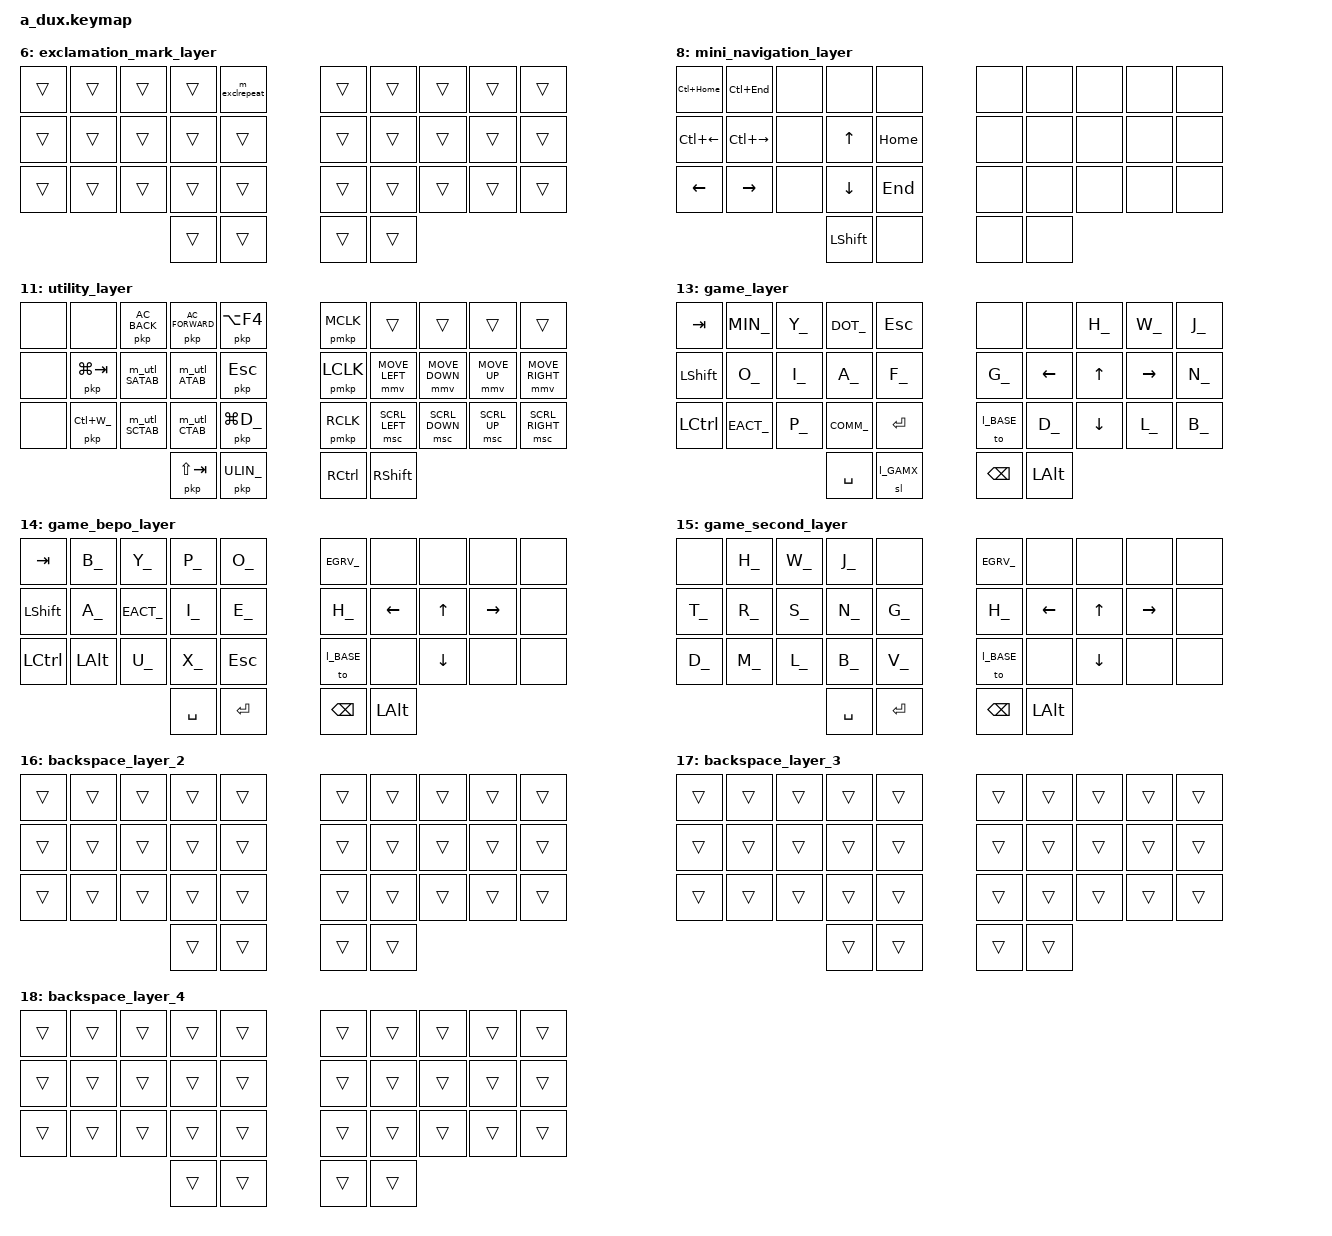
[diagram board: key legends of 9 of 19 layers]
#include <behaviors.dtsi>
#include <dt-bindings/zmk/keys.h>
#include <dt-bindings/zmk/bt.h>
#include <dt-bindings/zmk/outputs.h>
#include <dt-bindings/zmk/pointing.h>

#include "bepo_bindings.h"
#include "settings.dtsi"


// SPECIAL MODS ----------------------
#define SUPR(x)     LS(LC(LA(x)))
#define HYPR(x)  LG(LS(LC(LA(x))))

// EXTERNAL INTEGRATIONS ------------------------
#define M2_BRI_U     SUPR(U_)  // + brightness external display           (ahk + controlmymonitor)
#define M2_BRI_D     SUPR(Z_)  // - brightness external display           (ahk + controlmymonitor)
#define DISPLAY_OFF  SUPR(Q_)  // turns screen off                        (ahk + controlmymonitor)
#define TOG_DISPLAY  SUPR(Y_)  // toggles extend/external display         (ahk + controlmymonitor)
#define TOG_DCR      SUPR(I_)  // toggles DCR on/off on external display  (ahk + controlmymonitor)
#define PROC_EXP     HYPR(B_)  // opens process explorer                  (ahk)
#define TOG_THEME    HYPR(M_)  // toggles dark/light theme                (powertoys)

// LAYERS ----------------------------
#define l_BASE 0  // 
#define l_CAPS 1  // general-use caps layer (uppercase letters and sequences). preferrable to capslock to preserve hold-tap functions like .: and ?!
#define l_CPWD 2  // caps layer deactivated after space, tab, or layer change
#define l_OSCP 3  // one-shot caps
#define l_NUM  4  // numbers on LH, mathematical symbols on rh
#define l_SYM  5  // various symbols for coding and writing
#define l_EXCL 6  // holding ? inserts an exclamation mark; this allows it to then be repeated by tapping ? again within a time window
#define l_NAV  7  // text cursor navigation on RH, various functions on LH (notably undo, redo, cut, copy, paste)
#define l_MNAV 8  // allows for limited text cursor with LH only. activated by holding p
#define l_ACNT 9  // accented vowels on LH, dead-key and loose accents on RH
#define l_ACCP 10 // same as above but with uppercase accents, for use with caps layers
#define l_UTIL 11 // various utilities on LH, mouse movement on RH
#define l_FUNC 12 // special keys and bluetooth config on LH, F-keys on RH. activated by holding both LH thumb keys
#define l_GAME 13 // layer similar to base, with combos disabled for gaming
#define l_GAM2 14 // same but more closely modeled after bépo, for games that hard-code qwerty (must change OS input to qwerty)
#define l_GAMX 15 // extra keys for lh on game layers
#define l_BSP2 16 // |
#define l_BSP3 17 // | ephemeral layers for erasing 2- to 4-letter sequences with bksp when a corresponding macro is used
#define l_BSP4 18 // | 

// combos don't work on game layer (to minimize delay)
#define ll_DEFAULT     l_BASE  l_CAPS  l_CPWD  l_OSCP  l_NUM  l_SYM  l_EXCL  l_NAV  l_MNAV  l_ACNT  l_ACCP  l_BSP2 l_BSP3 l_BSP4
#define ll_NOTCPWD     l_BASE  l_CAPS                  l_NUM  l_SYM  l_EXCL  l_NAV  l_MNAV  l_ACNT  l_ACCP  l_BSP2 l_BSP3 l_BSP4
#define ll_NOTBSPC     l_BASE  l_CAPS  l_CPWD  l_OSCP  l_NUM  l_SYM  l_EXCL  l_NAV  l_MNAV  l_ACNT  l_ACCP
#define ll_CAPS                l_CAPS  l_CPWD  l_OSCP
#define ll_CPWD                        l_CPWD  l_OSCP


/ {
	
behaviors { 
    #include "behaviors.dtsi"
};
macros {
    #include "macros.dtsi"
};
combos {
    #include "combos.dtsi"
};

// BEHAVIORS -------------------------
// to   = enables only this layer
// tog  = toggle layer
// mo   = layer while held
// sk   = one-shot modifier
// sl   = one-shot layer
// mt   = hold-tap
// lt   = hold layer, tap kp
// mosl = mo on hold, sl on tap

keymap {
	compatible = "zmk,keymap";

 // READABILITY ------------------
	#define _pivot_       &none // button being held for accessing current layer
	#define xxxxxxxxx   &none
	#define xxxxxx      &none
	#define ______      &trans
	#define _________   &trans
	

 // HOME-ROW MODS ------------------
	#define HMLS   &htl  LSHIFT // LH shift prefers keys on RH
	#define HMRS   &htr  RSHIFT // and vice-versa
	#define HMLC   &htl  LCTRL
	#define HMRC   &htr  RCTRL
	#define HMLA   &htl  LALT
	#define HMRA   &htr  RALT
	#define HMLG   &htl  LGUI
	#define HMRG   &htr  RGUI
	
	// balanced hold-tap mods
	// todo: does this need to be positional?
	#define HBLS   &htb  LSHIFT
	#define HBRS   &htb  RSHIFT
	#define HBLC   &htb  LCTRL
	#define HBRC   &htb  RCTRL
	#define HBLA   &htb  LALT
	#define HBRA   &htb  RALT
	#define HBLG   &htb  LGUI
	#define HBRG   &htb  RGUI
	
	#define MNAV   &mokp l_MNAV // mini nav layer

 // HOME-ROW MODS (CAPS LAYER)
	#define HMLScw(X)   &htls_cw 0 LS(X)
	#define HMRScw(X)   &htrs_cw 0 LS(X)
	#define HMLCcw(X)   &htlc_cw 0 LS(X)
	#define HMRCcw(X)   &htrc_cw 0 LS(X)
	#define HMLAcw(X)   &htla_cw 0 LS(X)
	#define HMRAcw(X)   &htra_cw 0 LS(X)
	#define HMLGcw(X)   &htlg_cw 0 LS(X)
	#define HMRGcw(X)   &htrg_cw 0 LS(X)

 // HOLDTAP SYMBOLS ------------------               // HOLD  TAP
	#define DLLR_EURO    &htslow    EURO_  DLLR_     //  €     $
	#define EQUL_DIFF    &htslow    DIFF_  EQUL_     //  ≠     =
	#define IEXCL_IQMRK  &htslow    IEXC_  IQMR_     //  ¡     ¿
	#define EXCL_QMRK    &htslow    EXCL_  QMRK_     //  !     ?

	#define NBSP_QMRK    &ht_QMRK   0      QMRK_     // ■?     ?      // ■ = narrow nbsp
	#define NBSP_EXCL    &ht_EXCL   0      0         // ■!     !      
	#define DOT_COLN     &ht_COLN   0      DOT_      // ■:□    .      // □ = space
	#define COMM_SCLN    &ht_SCLN   0      COMM_     // ■;□    ,

	#define NBSP_LGLM    &ht_LGLM   LGLM_  0         //  «     «■
	#define NBSP_RGLM    &ht_RGLM   RGLM_  0         //  »      ■»
	
	#define LT_LARR      &ht_LT     0      LT_       //  ←      <
	#define GT_RARR      &ht_GT     0      GT_       //  →      >


 // THUMB KEYS ------------------
	#define lt_NUM_E           &lt   l_NUM      E_
	#define lt_NUM_E_cp        &lt   l_NUM   LS(E_)

	#define mosl_SYM          &mosl  l_SYM   l_SYM
	#define mosl_SYM_cw     &mo_slcw_l_SYM   l_SYM 0

	#define mosl_ACNT         &mosl  l_ACNT  l_ACNT
	#define mosl_ACCP         &mosl  l_ACCP  l_ACCP

	#define lt_NAV_SPC        &lt    l_NAV SPC
	#define lt_NAV_SPC_cw   &cw_mokp_l_NAV_SPC 0 0


 // -------------------
	#define UTLAYR    &mokp_l_UTIL 0    // UTIL layer on hold               : currently on u
	#define HMLG_OSCP &htsl LGUI l_OSCP // one-shift on touch, LGUI on hold : currently on bottom left pinky
	
 // ------------------------------------------------------------------------------------------------------------------        
 //                                                         BASE                     
 // ------------------------------------------------------------------------------------------------------------------        
	base_layer {bindings=<
 // -------------------
	HMLG_OSCP  HBLG MIN_  &kp  Y_  DOT_COLN      NBSP_QMRK        &kp K_     &kp  C_  &kp  H_  &kp  W_  &sl l_OSCP
	UTLAYR U_  HMLA O_    HMLC I_  HMLS A_       &kp F_           &kp G_     HMRS T_  HMRC R_  HMRA S_  &kp  N_
	&ht Q_ Z_  HMRA EACT_ MNAV P_  COMM_SCLN     &kp X_           &kp V_     &kp  D_  &kp  M_  HMLA L_  HMRG B_
	//  
									   lt_NUM_E  mosl_SYM         mosl_ACNT  lt_NAV_SPC
	>;};
	
	
 // --------------------------------------------------------------------------------------------------------------------------------------------------------
 //                                                                           CAPS
 // --------------------------------------------------------------------------------------------------------------------------------------------------------
	#define CAPSDEF \
		       &to l_BASE  HBLG  MIN_     &kp LS(Y_)  DOT_COLN    NBSP_QMRK         &kp LS(K_)  &kp LS(C_)  &kp LS(H_)  &kp LS(W_)  &to l_BASE   \
		    UTLAYR LS(U_)  HMLAcw(O_)	  HMLCcw(I_)  HMLScw(A_)  &kp LS(F_)        &kp LS(G_)  HMRScw(T_)  HMRCcw(R_)  HMRAcw(S_)  &kp LS(N_)   \
		&ht LS(Q_) LS(Z_)  HMRAcw(EACT_) MNAV LS(P_)  COMM_SCLN   &kp LS(X_)        &kp LS(V_)  &kp LS(D_)  &kp LS(M_)  HMLAcw(L_)  HMRGcw(B_)
// --------------------
	caps_layer {bindings=<
	CAPSDEF	//							 going to another layer does not leave caps layer
									lt_NUM_E_cp   mosl_SYM             mosl_ACCP   lt_NAV_SPC     >;};	
									
	capsword_layer {bindings=<
	CAPSDEF	//					      left thumb keys and main right thumb key leave caps layer
									lt_NUM_E_cp   mosl_SYM_cw          mosl_ACCP   lt_NAV_SPC_cw  >;};
									
	oneshotcaps_layer {bindings=<
		       &to l_BASE  HBLG  MIN_     &kp LS(Y_)  &kp COLN_    NBSP_QMRK         &kp LS(K_)   &kp LS(C_)  &kp LS(H_)  &kp LS(W_)  &to l_BASE
		    UTLAYR LS(U_)  HMLAcw(O_)	  HMLCcw(I_)  HMLScw(A_)   &kp LS(F_)        &kp LS(G_)   HMRScw(T_)  HMRCcw(R_)  HMRAcw(S_)  &kp LS(N_)
		&ht LS(Q_) LS(Z_)  HMRAcw(EACT_) MNAV LS(P_)  &kp SCLN_    &kp LS(X_)        &kp LS(V_)   &kp LS(D_)  &kp LS(M_)  HMLAcw(L_)  HMRGcw(B_)
						   lt_NUM_E_cp  ______         mosl_ACCP  ______
	>;};
	//old oneshotcaps layer: //TODO remove
	//CAPSDEF	//					  all thumb keys leave oneshotcaps (automatically, since it's one-shot!)
	//								lt_NUM_E_cp   mosl_SYM             mosl_ACCP   lt_NAV_SPC_cw  >;};
		// TWO DIFFERENCES OF ONESHOTCAPS
		// | * qu combo does Qu, not QU
        // | * default mosl_SYM behavior, since SLCP will be toggled off automatically. 
        // |   otherwise in a quick roll the second key will arrive after going to BASE and before sl'ing SYM
		
 // --------------------------------------------------------------------------------------------------------------------------------------------------------
 //                                                             NUMBERS
 // --------------------------------------------------------------------------------------------------------------------------------------------------------
 
	num_layer {bindings=<
 // can be locked by pressing Y on l_NAV
 // -------------------
	&kp  PIPE_   &kp  N7_   &kp  N8_   &kp  N9_      EXCL_QMRK             DLLR_EURO       &kp  LBRK_   &kp  RBRK_   HMRA HASH_   &kp  PCNT_
	HBLG N0_     HBLA N1_   HBLC N2_   HBLS N3_      &kp SCLN_             &kp COLN_       HMLS PLUS_   HMLC MIN_    HMLA STAR_   &kp  FSLA_
	DOT_COLN     &kp  N4_   MNAV N5_   &kp  N6_      COMM_SCLN             &kp DOT_        LT_LARR      GT_RARR      EQUL_DIFF    HMRG BSLA_
	
										   &to l_BASE   _pivot_            &kp ULIN_   ______
	>;}; //                                  unlock 
	
 // --------------------------------------------------------------------------------------------------------------------------------------------------------
 //                                                                   SYMBOLS
 // --------------------------------------------------------------------------------------------------------------------------------------------------------
	
 // -------------------
	symbol_layer {bindings=<
 // -------------------
	&kp  PIPE_   &kp  AT_     &kp  AE_     &kp  OE_        NBSP_EXCL            DLLR_EURO       &kp  LBRK_   &kp RBRK_    &kp AMPR_   &kp  TLDL_
	HBLG LCUR_   HBLA RCUR_   HBLC LPAR_   HBLS RPAR_      &kp PIPE_            &kp COLN_       HBRS CFXL_   HBRC GRVL_   &kp RALT    &kp  FSLA_
	&kp  NDSH_   HBRA MDSH_   NBSP_LGLM    NBSP_RGLM       xxxxxx	            &kp DOT_        LT_LARR      GT_RARR      HBLA EQUL_  HMRG BSLA_
	
													 xxxxxx   xxxxxx            &lt l_NUM ULIN_  ______
	>;}; //  								                double tap

 // -------------------
	exclamation_mark_layer {bindings=<
 // allows exclamation mark to be repeated by tapping after its long press
 // TODO: add other hold-tap kps
 // -------------------
	______ ______ ______ ______  &m_exclrepeat    ______    ______ ______ ______ ______
	______ ______ ______ ______    ______         ______    ______ ______ ______ ______
	______ ______ ______ ______    ______         ______    ______ ______ ______ ______
						   ______  ______         ______  ______
	>;};




 // -------------------
 // RH AUX LAYERS
 // -------------------
	#define TASKMAN      &htslow   PROC_EXP   LC(LS(ESC))  // hold: procexp, tap: taskman
	#define PASTEPLAIN   &kp LC(LG(LA(V_)))                // plaintext paste (power toys)
 // --------------------------------------------------------------------------------------------------------------------------------------------------------
 //                                                                        NAV
 // --------------------------------------------------------------------------------------------------------------------------------------------------------
	navigation_layer {bindings=<
 // -------------------       lock num layer
	&kp  LSLCK    &kp  LNLCK    &to  l_NUM   PASTEPLAIN			TASKMAN			xxxxxx   HBLS LC(HOME)   HBLC PG_DN    HBLA PG_UP    HBRG LC(END)
	&kp  LC(Z_)   HBLA LC(X_)   HBLC LC(C_)  HBLS LC(V_)       &kp CAPS			xxxxxx   &kp  LC(LEFT)   &kp  DOWN     &kp  UP       &kp  LC(RIGHT)
	HBLG LC(Y_)   HBRA INSERT   &kp  PSCRN   &kp  PSBRK       xxxxxxxxx			xxxxxx   &kp  HOME       &kp  LEFT     &kp  RIGHT    &kp  END
	//  					                                        				                  
											  &tog l_CPWD   &tog l_CAPS			xxxxxx   _pivot_
	>;};

 // -------------------	
	mini_navigation_layer {bindings=<
 // accessed by holding P
 // -------------------
	&kp LC(HOME)  &kp LC(END)    xxxxxx    xxxxxxxxx	xxxxxxxxx			xxxxxx   xxxxxxxxx   xxxxxxxxx   xxxxxxxxx   xxxxxxxxx
	&kp LC(LEFT)  &kp LC(RIGHT)  xxxxxx    &kp UP		&kp HOME			xxxxxx   xxxxxxxxx   xxxxxxxxx   xxxxxxxxx   xxxxxxxxx
	&kp    LEFT   &kp    RIGHT   _pivot_   &kp DOWN		&kp  END			xxxxxx   xxxxxxxxx   xxxxxxxxx   xxxxxxxxx   xxxxxxxxx
	//  					                                        				                  
												&kp LSHIFT  xxxxxx			xxxxxx   xxxxxx
	>;};

 // --------------------------------------------------------------------------------------------------------------------------------------------------------
 //                                                                     ACCENTS (l_ACNT)
 // --------------------------------------------------------------------------------------------------------------------------------------------------------
    // questionable syntactic sugar to define several parameters beginning with &m_
	#define MACRO_ROW_3(PREFIX, ONE, TWO, THREE)               &m_##PREFIX##ONE &m_##PREFIX##TWO &m_##PREFIX##THREE
	#define MACRO_ROW_4(PREFIX, ONE, TWO, THREE, FOUR)         &m_##PREFIX##ONE &m_##PREFIX##TWO &m_##PREFIX##THREE &m_##PREFIX##FOUR
	#define MACRO_ROW_5(PREFIX, ONE, TWO, THREE, FOUR, FIVE)   &m_##PREFIX##ONE &m_##PREFIX##TWO &m_##PREFIX##THREE &m_##PREFIX##FOUR &m_##PREFIX##FIVE
	
    #define HMCP &mokp l_ACCP // otherwise shift is applied to ralt and messes up some keys.
                              // TODO maybe replace by transp shift layer + conditional ACCP?
	accent_layer {bindings=<
 // -------------------
 MACRO_ROW_4(,    CFLX_U_,   CFLX_O_,   CFLX_I_,   CFLX_A_ )     IEXCL_IQMRK       xxxxxx     &kp  CCED_  &kp  APST_  &kp  QUOT_   &m_B_J_
 MACRO_ROW_5(,    ACUT_U_,   ACUT_O_,   ACUT_I_,   ACUT_A_,          TILD_A_)      xxxxxx     HMCP CFLX_  HMRC GRAV_  HMLA ACUT_   &m_TILD_N_
 MACRO_ROW_3(,    GRAV_U_,   TILD_O_,   TRMA_I_ )  &kp AGRV_          xxxxxx       xxxxxx     &kp  TRMA_  xxxxxxxxx     &m_SZTT   &kp TILD_

											          &m_CFLX_E_   &kp EGRV_       xxxxxx   ______
	>;}; //  								                                     double tap

 // -------------------
	accent_caps_layer {bindings=<
 // -------------------
 MACRO_ROW_4(cp_, CFLX_U_,   CFLX_O_,   CFLX_I_,   CFLX_A_ )           xxxxxx           xxxxxx       &kp  LS(CCED_)  &kp  APST_  &kp  QUOT_  &m_cp_B_J_
 MACRO_ROW_5(cp_, ACUT_U_,   ACUT_O_,   ACUT_I_,   ACUT_A_,           TILD_A_)          xxxxxx       HMRS ACUT_      HMRC CFLX_  HMLA GRAV_  &m_cp_TILD_N_
 MACRO_ROW_3(cp_, GRAV_U_,   TILD_O_,   TRMA_I_)   &kp LS(AGRV_)       xxxxxx           xxxxxx       &kp  TRMA_      xxxxxxxxx   &m_cp_SZTT  &kp   TILD_

										      &m_cp_CFLX_E_   &kp LS(EGRV_)       		xxxxxx   ______
	>;};//  		   							                                     double tap

 // --------------------------------------------------------------------------------------------------------------------------------------------------------
 //                                                                     UTILITY
 // --------------------------------------------------------------------------------------------------------------------------------------------------------
	utility_layer {bindings=<
 // -------------------                                                                      
	xxxxxx   xxxxxx   	  &pkp C_AC_BACK  &pkp C_AC_FORWARD &pkp LA(F4)         &pmkp MCLK   _________       _________       _________     _________
	_pivot_  &pkp LG(TAB) &m_utl_SATAB 	  &m_utl_ATAB		&pkp ESC        	&pmkp LCLK   &mmv MOVE_LEFT  &mmv MOVE_DOWN  &mmv MOVE_UP  &mmv MOVE_RIGHT
	xxxxxx   &pkp LC(W_)  &m_utl_SCTAB    &m_utl_CTAB       &pkp LG(D_)         &pmkp RCLK   &msc SCRL_LEFT  &msc SCRL_DOWN  &msc SCRL_UP  &msc SCRL_RIGHT
	
											 &pkp LS(TAB)   &pkp ULIN_          &kp RCTRL   &kp RSHIFT
	>;};

 // ------------------------------------------------------------------------------------------------------------------------------------------
 //                                                                                FUNCTION
 // ------------------------------------------------------------------------------------------------------------------------------------------
	function_layer {bindings=<
 // -------------------		
	&bt  BT_SEL 3   &bt  BT_SEL 0   &bt  BT_SEL 1   &bt  BT_SEL 2      &bt   BT_CLR         &sk LALT       &kp F7  &kp F8  &kp F9  &kp F12
	HMLG C_BRI_UP   HMLA M2_BRI_U   HMLC C_VOL_UP   HMLS C_PP  	       &out OUT_BLE         &sk LSHIFT     &kp F1  &kp F2  &kp F3  &kp F10
	&kp  C_BRI_DN   &kp  M2_BRI_D   &kp  C_VOL_DN   &kp  C_MUTE        &out OUT_USB         &sk LCTRL      &kp F4  &kp F5  &kp F6  &kp F11
	//
																  _pivot_   _pivot_         &kp LSHIFT   &kp LALT
	>;};

 // --------------------------------------------------------------------------------------------------------------------
 //                                                       GAMING
 // --------------------------------------------------------------------------------------------------------------------
  game_layer {bindings=<
 // similar to base layer
 // -------------------
	&kp TAB     &kp MIN_  &kp Y_  &kp DOT_		&kp ESC           &kp  K_		&kp C_    &kp H_    &kp W_     &kp J_
	&kp LSHIFT  &kp O_    &kp I_  &kp A_		&kp F_            &kp  G_		&kp LEFT  &kp UP    &kp RIGHT  &kp N_
	&kp LCTRL   &kp EACT_ &kp P_  &kp COMM_		&kp ENTER         &to l_BASE	&kp D_    &kp DOWN  &kp L_     &kp B_
	//
								  &kp SPACE     &sl l_GAMX         &kp BSPC   &kp LALT
	>;};

 // -------------------
 // BÉPO GAMING
 // more closely modeled after bépo, for games that hard-code qwerty
	game_bepo_layer {bindings=<
 // -------------------	
	&kp TAB     &kp B_    &kp Y_    &kp P_		&kp O_            &kp EGRV_  		xxxxxx    xxxxxx    xxxxxx     xxxxxx
	&kp LSHIFT  &kp A_    &kp EACT_ &kp I_		&kp E_            &kp  H_  			&kp LEFT  &kp UP    &kp RIGHT  xxxxxx
	&kp LCTRL   &kp LALT  &kp U_    &kp X_		&kp ESC           &to l_BASE  		xxxxxx    &kp DOWN  xxxxxx     xxxxxx
	//
									&kp SPACE  &kp ENTER          &kp BSPC  &kp LALT
	>;};

 // -------------------
 // GAMING SECOND LAYER
 // extra keys on lh
	game_second_layer {bindings=<
 // -------------------	
	&kp C_  &kp H_  &kp W_  &kp J_    &kp K_            &kp EGRV_  		xxxxxx    xxxxxx    xxxxxx     xxxxxx
	&kp T_  &kp R_  &kp S_  &kp N_	  &kp G_            &kp  H_  		&kp LEFT  &kp UP    &kp RIGHT  xxxxxx
	&kp D_  &kp M_  &kp L_  &kp B_	  &kp V_            &to l_BASE  	xxxxxx    &kp DOWN  xxxxxx     xxxxxx
	//
						&kp SPACE  &kp ENTER            &kp BSPC  &kp LALT
	>;};

 // ----------------------------------------------------------------------------------------
 //                                   BACKSPACE LAYERS
 // when active, multiple characters inserted by a macro will be deleted together by bksp
 // ----------------------------------------------------------------------------------------
 
	backspace_layer_2 {bindings=<
	______ ______ ______ ______    ______         ______    ______ ______ ______ ______
	______ ______ ______ ______    ______         ______    ______ ______ ______ ______
	______ ______ ______ ______    ______         ______    ______ ______ ______ ______
						 ______  ______             ______  ______
	>;};
	
	backspace_layer_3 {bindings=<
	______ ______ ______ ______    ______         ______    ______ ______ ______ ______
	______ ______ ______ ______    ______         ______    ______ ______ ______ ______
	______ ______ ______ ______    ______         ______    ______ ______ ______ ______
						 ______  ______             ______  ______
	>;};
	
	backspace_layer_4 {bindings=<
	______ ______ ______ ______    ______         ______    ______ ______ ______ ______
	______ ______ ______ ______    ______         ______    ______ ______ ______ ______
	______ ______ ______ ______    ______         ______    ______ ______ ______ ______
						 ______  ______             ______  ______
	>;};
 
 // ----------------------------------------------------------------------------------------
 //                                          DEBUGGING
 // ----------------------------------------------------------------------------------------
 /*
 	bindings = <
 		xxxxxx xxxxxx xxxxxx xxxxxx    xxxxxx         xxxxxx    xxxxxx xxxxxx xxxxxx _____
 		xxxxxx xxxxxx xxxxxx xxxxxx    xxxxxx         xxxxxx    xxxxxx xxxxxx xxxxxx _____
 		xxxxxx xxxxxx xxxxxx xxxxxx    xxxxxx         xxxxxx    xxxxxx xxxxxx xxxxxx _____
 	                           xxxxxx  xxxxxx         xxxxxx  xxxxxx
 	>;
	
 	bindings = <
		______ ______ ______ ______    ______         ______    ______ ______ ______ ______
		______ ______ ______ ______    ______         ______    ______ ______ ______ ______
		______ ______ ______ ______    ______         ______    ______ ______ ______ ______
		                     ______  ______             ______  ______
	>;
 */
 };
 };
